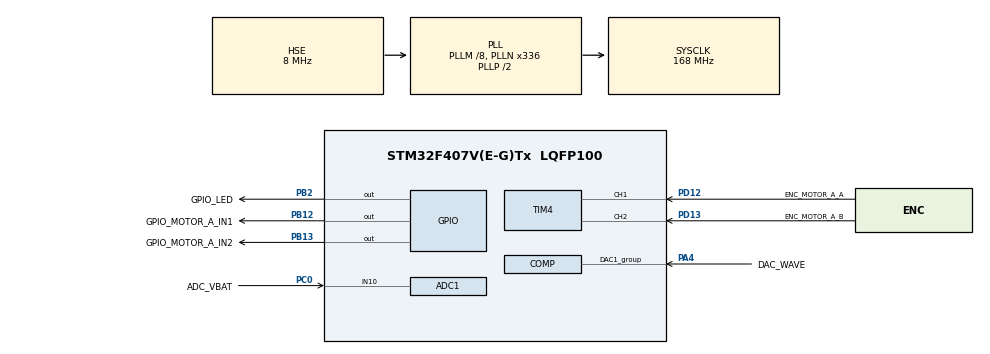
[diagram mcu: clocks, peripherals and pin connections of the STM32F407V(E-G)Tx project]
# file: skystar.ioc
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# 【合成样例】按 STM32CubeMX 6.x .ioc 格式手写的子集，用于 tools/ioc_import.py 的测试与演示；
# 不保证 CubeMX 能直接打开。真实工程请在 CubeMX 里按 docs/05-CubeMX工作流.md 的标签约定配置后保存覆盖本文件。
Mcu.Family=STM32F4
Mcu.Name=STM32F407V(E-G)Tx
Mcu.Package=LQFP100
ProjectManager.TargetToolchain=Makefile
RCC.HSE_VALUE=8000000
RCC.SYSCLKFreq_VALUE=168000000
RCC.APB1CLKDivider=RCC_HCLK_DIV4
RCC.APB2CLKDivider=RCC_HCLK_DIV2
RCC.APB1TimFreq_Value=84000000
RCC.APB2TimFreq_Value=168000000
NVIC.PriorityGroup=NVIC_PRIORITYGROUP_4
NVIC.TIM6_DAC_IRQn=true\:1\:0\:false\:false\:true\:true\:true\:true
NVIC.USART1_IRQn=true\:5\:0\:false\:false\:true\:true\:true\:true
NVIC.USART2_IRQn=true\:5\:0\:false\:false\:true\:true\:true\:true
NVIC.DMA2_Stream0_IRQn=true\:5\:0\:false\:false\:true\:false\:true\:true
NVIC.DMA2_Stream2_IRQn=true\:5\:0\:false\:false\:true\:false\:true\:true
NVIC.DMA2_Stream7_IRQn=true\:5\:0\:false\:false\:true\:false\:true\:true
NVIC.DMA1_Stream5_IRQn=true\:5\:0\:false\:false\:true\:false\:true\:true
NVIC.DMA1_Stream6_IRQn=true\:5\:0\:false\:false\:true\:false\:true\:true
PB2.Signal=GPIO_Output
PB2.GPIO_Label=GPIO_LED
PB12.Signal=GPIO_Output
PB12.GPIO_Label=GPIO_MOTOR_A_IN1
PB13.Signal=GPIO_Output
PB13.GPIO_Label=GPIO_MOTOR_A_IN2
PA8.Signal=S_TIM1_CH1
PA8.GPIO_Label=PWM_MOTOR_A
PC6.Signal=S_TIM3_CH1
PC6.GPIO_Label=PWM_SERVO_X
PC7.Signal=S_TIM3_CH2
PC7.GPIO_Label=PWM_SERVO_Y
TIM1.Channel-PWM\ Generation1\ CH1=TIM_CHANNEL_1
TIM1.Prescaler=0
TIM1.Period=8399
TIM3.Channel-PWM\ Generation1\ CH1=TIM_CHANNEL_1
TIM3.Channel-PWM\ Generation2\ CH2=TIM_CHANNEL_2
TIM3.Prescaler=83
TIM3.Period=19999
PD12.Signal=S_TIM4_CH1
PD12.GPIO_Label=ENC_MOTOR_A_A
PD13.Signal=S_TIM4_CH2
PD13.GPIO_Label=ENC_MOTOR_A_B
SH.S_TIM4_CH1.0=TIM4_CH1,Encoder_Interface
SH.S_TIM4_CH2.0=TIM4_CH2,Encoder_Interface
TIM4.EncoderMode=TIM_ENCODERMODE_TI12
TIM4.IC1Filter=6
VP_TIM6_VS_ClockSourceINT.Mode=Enable_Timer
TIM6.Prescaler=83
TIM6.Period=999
PA9.Signal=USART1_TX
PA9.GPIO_Label=UART_LINK_TX
PA10.Signal=USART1_RX
PA10.GPIO_Label=UART_LINK_RX
USART1.BaudRate=460800
PA2.Signal=USART2_TX
PA2.GPIO_Label=UART_VISION_TX
PA3.Signal=USART2_RX
PA3.GPIO_Label=UART_VISION_RX
USART2.BaudRate=115200
PA4.Signal=COMP_DAC1_group
PA4.GPIO_Label=DAC_WAVE
PA4.Mode=DAC_OUT1
PC0.Signal=ADCx_IN10
PC0.GPIO_Label=ADC_VBAT
SH.ADCx_IN10.0=ADC1_IN10,IN10
Dma.Request0=USART1_RX
Dma.Request1=USART1_TX
Dma.Request2=USART2_RX
Dma.Request3=USART2_TX
Dma.Request4=ADC1
Dma.USART1_RX.0.Instance=DMA2_Stream2
Dma.USART1_RX.0.Direction=DMA_PERIPH_TO_MEMORY
Dma.USART1_RX.0.Mode=DMA_CIRCULAR
Dma.USART1_TX.1.Instance=DMA2_Stream7
Dma.USART1_TX.1.Direction=DMA_MEMORY_TO_PERIPH
Dma.USART1_TX.1.Mode=DMA_NORMAL
Dma.USART2_RX.2.Instance=DMA1_Stream5
Dma.USART2_RX.2.Direction=DMA_PERIPH_TO_MEMORY
Dma.USART2_RX.2.Mode=DMA_CIRCULAR
Dma.USART2_TX.3.Instance=DMA1_Stream6
Dma.USART2_TX.3.Direction=DMA_MEMORY_TO_PERIPH
Dma.USART2_TX.3.Mode=DMA_NORMAL
Dma.ADC1.4.Instance=DMA2_Stream0
Dma.ADC1.4.Direction=DMA_PERIPH_TO_MEMORY
Dma.ADC1.4.Mode=DMA_NORMAL
Dma.ADC1.4.PeriphDataAlignment=DMA_PDATAALIGN_HALFWORD
Dma.ADC1.4.MemDataAlignment=DMA_MDATAALIGN_HALFWORD
TIM2.Prescaler=0
TIM2.Period=839
TIM2.TIM_MasterOutputTrigger=TIM_TRGO_UPDATE
VP_TIM2_VS_ClockSourceINT.Mode=Internal

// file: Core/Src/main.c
/* USER CODE BEGIN Header */
/**
 * 【合成样例】按 STM32CubeMX 6.x（STM32CubeF4）生成代码的结构手写，用于在没有 CubeMX 的环境里
 * 编译验证 ports/stm32-cubemx。**不是 CubeMX 的真实输出，未上板测试。**
 * 正式使用：CubeMX 打开 ../skystar.ioc → GENERATE CODE。CubeMX 只保留 USER CODE 区，
 * 本工程与框架的接缝只有下面 3 处 USER CODE（Includes / 2 / 3）。
 */
/* USER CODE END Header */
#include "main.h"

/* USER CODE BEGIN Includes */
#include "dz_cubemx.h"
/* USER CODE END Includes */

ADC_HandleTypeDef hadc1;
DAC_HandleTypeDef hdac;
TIM_HandleTypeDef htim1;
TIM_HandleTypeDef htim2;
TIM_HandleTypeDef htim3;
TIM_HandleTypeDef htim4;
TIM_HandleTypeDef htim6;
UART_HandleTypeDef huart1;
UART_HandleTypeDef huart2;
DMA_HandleTypeDef hdma_adc1;
DMA_HandleTypeDef hdma_usart1_rx;
DMA_HandleTypeDef hdma_usart1_tx;
DMA_HandleTypeDef hdma_usart2_rx;
DMA_HandleTypeDef hdma_usart2_tx;

void SystemClock_Config(void);
static void MX_GPIO_Init(void);
static void MX_DMA_Init(void);
static void MX_ADC1_Init(void);
static void MX_DAC_Init(void);
static void MX_TIM1_Init(void);
static void MX_TIM2_Init(void);
static void MX_TIM3_Init(void);
static void MX_TIM4_Init(void);
static void MX_TIM6_Init(void);
static void MX_USART1_UART_Init(void);
static void MX_USART2_UART_Init(void);
void HAL_TIM_MspPostInit(TIM_HandleTypeDef *htim);

int main(void)
{
  HAL_Init();
  SystemClock_Config();
  MX_GPIO_Init();
  MX_DMA_Init();
  MX_ADC1_Init();
  MX_DAC_Init();
  MX_TIM1_Init();
  MX_TIM2_Init();
  MX_TIM3_Init();
  MX_TIM4_Init();
  MX_TIM6_Init();
  MX_USART1_UART_Init();
  MX_USART2_UART_Init();
  /* USER CODE BEGIN 2 */
  dz_cubemx_start();
  /* USER CODE END 2 */
  while (1)
  {

    /* USER CODE BEGIN 3 */
    dz_cubemx_loop();
  }
  /* USER CODE END 3 */
}

void SystemClock_Config(void)
{
  RCC_OscInitTypeDef RCC_OscInitStruct = {0};
  RCC_ClkInitTypeDef RCC_ClkInitStruct = {0};
  __HAL_RCC_PWR_CLK_ENABLE();
  __HAL_PWR_VOLTAGESCALING_CONFIG(PWR_REGULATOR_VOLTAGE_SCALE1);
  RCC_OscInitStruct.OscillatorType = RCC_OSCILLATORTYPE_HSE;
  RCC_OscInitStruct.HSEState = RCC_HSE_ON;
  RCC_OscInitStruct.PLL.PLLState = RCC_PLL_ON;
  RCC_OscInitStruct.PLL.PLLSource = RCC_PLLSOURCE_HSE;
  RCC_OscInitStruct.PLL.PLLM = 8;
  RCC_OscInitStruct.PLL.PLLN = 336;
  RCC_OscInitStruct.PLL.PLLP = RCC_PLLP_DIV2;
  RCC_OscInitStruct.PLL.PLLQ = 7;
  if (HAL_RCC_OscConfig(&RCC_OscInitStruct) != HAL_OK) Error_Handler();
  RCC_ClkInitStruct.ClockType = RCC_CLOCKTYPE_HCLK|RCC_CLOCKTYPE_SYSCLK|RCC_CLOCKTYPE_PCLK1|RCC_CLOCKTYPE_PCLK2;
  RCC_ClkInitStruct.SYSCLKSource = RCC_SYSCLKSOURCE_PLLCLK;
  RCC_ClkInitStruct.AHBCLKDivider = RCC_SYSCLK_DIV1;
  RCC_ClkInitStruct.APB1CLKDivider = RCC_HCLK_DIV4;
  RCC_ClkInitStruct.APB2CLKDivider = RCC_HCLK_DIV2;
  if (HAL_RCC_ClockConfig(&RCC_ClkInitStruct, FLASH_LATENCY_5) != HAL_OK) Error_Handler();
}

static void MX_ADC1_Init(void)
{
  ADC_ChannelConfTypeDef sConfig = {0};
  hadc1.Instance = ADC1;
  hadc1.Init.ClockPrescaler = ADC_CLOCK_SYNC_PCLK_DIV4;
  hadc1.Init.Resolution = ADC_RESOLUTION_12B;
  hadc1.Init.ScanConvMode = DISABLE;
  hadc1.Init.ContinuousConvMode = DISABLE;
  hadc1.Init.DiscontinuousConvMode = DISABLE;
  hadc1.Init.ExternalTrigConvEdge = ADC_EXTERNALTRIGCONVEDGE_NONE;
  hadc1.Init.ExternalTrigConv = ADC_SOFTWARE_START;
  hadc1.Init.DataAlign = ADC_DATAALIGN_RIGHT;
  hadc1.Init.NbrOfConversion = 1;
  hadc1.Init.DMAContinuousRequests = DISABLE;
  hadc1.Init.EOCSelection = ADC_EOC_SINGLE_CONV;
  if (HAL_ADC_Init(&hadc1) != HAL_OK) Error_Handler();
  sConfig.Channel = ADC_CHANNEL_10;
  sConfig.Rank = 1;
  sConfig.SamplingTime = ADC_SAMPLETIME_84CYCLES;
  if (HAL_ADC_ConfigChannel(&hadc1, &sConfig) != HAL_OK) Error_Handler();
}

static void pwm_init(TIM_HandleTypeDef *h, TIM_TypeDef *inst, uint32_t psc, uint32_t arr, const uint32_t *chs, int n)
{
  /* 注：CubeMX 实际会把每个 MX_TIMx_Init 展开写；此处合并只为样例简短，生成效果相同。 */
  TIM_OC_InitTypeDef sConfigOC = {0};
  h->Instance = inst;
  h->Init.Prescaler = psc;
  h->Init.CounterMode = TIM_COUNTERMODE_UP;
  h->Init.Period = arr;
  h->Init.ClockDivision = TIM_CLOCKDIVISION_DIV1;
  h->Init.RepetitionCounter = 0;
  h->Init.AutoReloadPreload = TIM_AUTORELOAD_PRELOAD_ENABLE;
  if (HAL_TIM_PWM_Init(h) != HAL_OK) Error_Handler();
  sConfigOC.OCMode = TIM_OCMODE_PWM1;
  sConfigOC.Pulse = 0;
  sConfigOC.OCPolarity = TIM_OCPOLARITY_HIGH;
  sConfigOC.OCFastMode = TIM_OCFAST_DISABLE;
  for (int i = 0; i < n; i++)
    if (HAL_TIM_PWM_ConfigChannel(h, &sConfigOC, chs[i]) != HAL_OK) Error_Handler();
  HAL_TIM_MspPostInit(h);
}

static void MX_TIM1_Init(void)
{
  static const uint32_t ch[] = {TIM_CHANNEL_1};
  TIM_BreakDeadTimeConfigTypeDef bdt = {0};
  pwm_init(&htim1, TIM1, 0, 8399, ch, 1);           /* 168 MHz / 8400 = 20 kHz */
  bdt.OffStateRunMode = TIM_OSSR_DISABLE; bdt.OffStateIDLEMode = TIM_OSSI_DISABLE;
  bdt.LockLevel = TIM_LOCKLEVEL_OFF; bdt.BreakState = TIM_BREAK_DISABLE;
  bdt.BreakPolarity = TIM_BREAKPOLARITY_HIGH; bdt.AutomaticOutput = TIM_AUTOMATICOUTPUT_DISABLE;
  if (HAL_TIMEx_ConfigBreakDeadTime(&htim1, &bdt) != HAL_OK) Error_Handler();
}

static void MX_TIM3_Init(void)
{
  static const uint32_t ch[] = {TIM_CHANNEL_1, TIM_CHANNEL_2};
  pwm_init(&htim3, TIM3, 83, 19999, ch, 2);         /* 84 MHz / 84 / 20000 = 50 Hz */
}

static void MX_TIM4_Init(void)
{
  TIM_Encoder_InitTypeDef sConfig = {0};
  htim4.Instance = TIM4;
  htim4.Init.Prescaler = 0;
  htim4.Init.CounterMode = TIM_COUNTERMODE_UP;
  htim4.Init.Period = 65535;
  htim4.Init.ClockDivision = TIM_CLOCKDIVISION_DIV1;
  htim4.Init.AutoReloadPreload = TIM_AUTORELOAD_PRELOAD_DISABLE;
  sConfig.EncoderMode = TIM_ENCODERMODE_TI12;
  sConfig.IC1Polarity = TIM_ICPOLARITY_RISING; sConfig.IC1Selection = TIM_ICSELECTION_DIRECTTI;
  sConfig.IC1Prescaler = TIM_ICPSC_DIV1; sConfig.IC1Filter = 6;
  sConfig.IC2Polarity = TIM_ICPOLARITY_RISING; sConfig.IC2Selection = TIM_ICSELECTION_DIRECTTI;
  sConfig.IC2Prescaler = TIM_ICPSC_DIV1; sConfig.IC2Filter = 6;
  if (HAL_TIM_Encoder_Init(&htim4, &sConfig) != HAL_OK) Error_Handler();
}

static void MX_TIM2_Init(void)
{
  /* ADC 块采样触发源（board.yaml adc.VBAT.block）：PSC/ARR 由移植层按采样率运行时改写，TRGO = 更新事件 */
  TIM_MasterConfigTypeDef m = {0};
  htim2.Instance = TIM2;
  htim2.Init.Prescaler = 0;
  htim2.Init.CounterMode = TIM_COUNTERMODE_UP;
  htim2.Init.Period = 839;
  htim2.Init.ClockDivision = TIM_CLOCKDIVISION_DIV1;
  htim2.Init.AutoReloadPreload = TIM_AUTORELOAD_PRELOAD_DISABLE;
  if (HAL_TIM_Base_Init(&htim2) != HAL_OK) Error_Handler();
  m.MasterOutputTrigger = TIM_TRGO_UPDATE;
  m.MasterSlaveMode = TIM_MASTERSLAVEMODE_DISABLE;
  if (HAL_TIMEx_MasterConfigSynchronization(&htim2, &m) != HAL_OK) Error_Handler();
}

static void MX_TIM6_Init(void)
{
  htim6.Instance = TIM6;
  htim6.Init.Prescaler = 83;
  htim6.Init.CounterMode = TIM_COUNTERMODE_UP;
  htim6.Init.Period = 999;
  htim6.Init.AutoReloadPreload = TIM_AUTORELOAD_PRELOAD_DISABLE;
  if (HAL_TIM_Base_Init(&htim6) != HAL_OK) Error_Handler();
}

static void uart_init(UART_HandleTypeDef *h, USART_TypeDef *inst, uint32_t baud)
{
  h->Instance = inst;
  h->Init.BaudRate = baud;
  h->Init.WordLength = UART_WORDLENGTH_8B;
  h->Init.StopBits = UART_STOPBITS_1;
  h->Init.Parity = UART_PARITY_NONE;
  h->Init.Mode = UART_MODE_TX_RX;
  h->Init.HwFlowCtl = UART_HWCONTROL_NONE;
  h->Init.OverSampling = UART_OVERSAMPLING_16;
  if (HAL_UART_Init(h) != HAL_OK) Error_Handler();
}
static void MX_USART1_UART_Init(void) { uart_init(&huart1, USART1, 460800); }
static void MX_USART2_UART_Init(void) { uart_init(&huart2, USART2, 115200); }

static void MX_DAC_Init(void)
{
  DAC_ChannelConfTypeDef sConfig = {0};
  hdac.Instance = DAC;
  if (HAL_DAC_Init(&hdac) != HAL_OK) Error_Handler();
  sConfig.DAC_Trigger = DAC_TRIGGER_NONE;
  sConfig.DAC_OutputBuffer = DAC_OUTPUTBUFFER_ENABLE;
  if (HAL_DAC_ConfigChannel(&hdac, &sConfig, DAC_CHANNEL_1) != HAL_OK) Error_Handler();
}

static void MX_DMA_Init(void)
{
  __HAL_RCC_DMA1_CLK_ENABLE();
  __HAL_RCC_DMA2_CLK_ENABLE();
  HAL_NVIC_SetPriority(DMA1_Stream5_IRQn, 5, 0); HAL_NVIC_EnableIRQ(DMA1_Stream5_IRQn);
  HAL_NVIC_SetPriority(DMA1_Stream6_IRQn, 5, 0); HAL_NVIC_EnableIRQ(DMA1_Stream6_IRQn);
  HAL_NVIC_SetPriority(DMA2_Stream0_IRQn, 5, 0); HAL_NVIC_EnableIRQ(DMA2_Stream0_IRQn);
  HAL_NVIC_SetPriority(DMA2_Stream2_IRQn, 5, 0); HAL_NVIC_EnableIRQ(DMA2_Stream2_IRQn);
  HAL_NVIC_SetPriority(DMA2_Stream7_IRQn, 5, 0); HAL_NVIC_EnableIRQ(DMA2_Stream7_IRQn);
}

static void MX_GPIO_Init(void)
{
  GPIO_InitTypeDef GPIO_InitStruct = {0};
  __HAL_RCC_GPIOH_CLK_ENABLE();
  __HAL_RCC_GPIOA_CLK_ENABLE();
  __HAL_RCC_GPIOB_CLK_ENABLE();
  __HAL_RCC_GPIOC_CLK_ENABLE();
  __HAL_RCC_GPIOD_CLK_ENABLE();
  HAL_GPIO_WritePin(GPIOB, GPIO_LED_Pin|GPIO_MOTOR_A_IN1_Pin|GPIO_MOTOR_A_IN2_Pin, GPIO_PIN_RESET);
  GPIO_InitStruct.Pin = GPIO_LED_Pin|GPIO_MOTOR_A_IN1_Pin|GPIO_MOTOR_A_IN2_Pin;
  GPIO_InitStruct.Mode = GPIO_MODE_OUTPUT_PP;
  GPIO_InitStruct.Pull = GPIO_NOPULL;
  GPIO_InitStruct.Speed = GPIO_SPEED_FREQ_LOW;
  HAL_GPIO_Init(GPIOB, &GPIO_InitStruct);
}

void Error_Handler(void)
{
  __disable_irq();
  while (1) { }
}
